# liliumSOC1_sysctrl register map
Vendor: Nordic Semiconductor; Series: liliumSOC1; File version: 1
Registers are 32-bit, read-write, reset 0x0 unless marked. A register's access mark holds for its fields unless they carry their own. Offsets are from the block's base; [hi:lo] are bit positions; lines under a group give offsets from that group; {n}, {i} and the like mark numbered series; 'fields as' and 'values as' point back to an identical list.

## POWER_S — POWER
Base 0x5F960000
0x00 TASKS_SEMAPHORE group — Peripheral tasks.
  0x00 ACQUIRE wo — Acquire the semaphore for regulator voltage scaling procedure.
    [0] ACQUIRE
      1=Trigger task
  0x04 RELEASE wo — Release the semaphore for regulator voltage scaling procedure.
    [0] RELEASE
      1=Trigger task
0x08 TASKS_REGUPDATE wo — Update the regulator configuration.
  [0] TASKS_REGUPDATE
    1=Trigger task
0x0C TASKS_TDDPDREQCLR wo — Clear the power domain request for Trace data and debug (TDD).
  [0] TASKS_TDDPDREQCLR
    1=Trigger task
0x100 EVENTS_SEMAPHORE group — Peripheral events.
  0x00 ACQUIRED — Acquired the semaphore for regulator voltage scaling procedure.
    [0] ACQUIRED
      0=NotGenerated (Event not generated); 1=Generated (Event generated)
  0x04 RELEASED — Released the semaphore for regulator voltage scaling procedure.
    [0] RELEASED
      values as EVENTS_SEMAPHORE.ACQUIRED.ACQUIRED
0x108 EVENTS_REGUPDATED — Updated the regulator configuration.
  [0] EVENTS_REGUPDATED
    values as EVENTS_SEMAPHORE.ACQUIRED.ACQUIRED
{0x10C+4i} EVENTS_ABBLOCK[{i}] (i=0..2) — Description collection: ABB lock for the ABB domain [n]
  [0] EVENTS_ABBLOCK — ABB lock for the ABB domain [n]
    values as EVENTS_SEMAPHORE.ACQUIRED.ACQUIRED
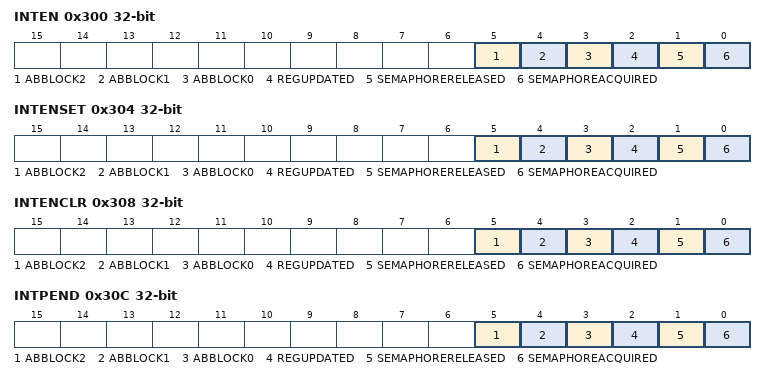
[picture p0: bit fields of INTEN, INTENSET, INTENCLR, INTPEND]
0x300 INTEN — Enable or disable interrupt
  [all] fields
    0=Disabled; 1=Enabled
  [5] ABBLOCK2 — Enable or disable interrupt for event ABBLOCK[2]
  [4] ABBLOCK1 — Enable or disable interrupt for event ABBLOCK[1]
  [3] ABBLOCK0 — Enable or disable interrupt for event ABBLOCK[0]
  [2] REGUPDATED — Enable or disable interrupt for event REGUPDATED
  [1] SEMAPHORERELEASED — Enable or disable interrupt for event SEMAPHORERELEASED
  [0] SEMAPHOREACQUIRED — Enable or disable interrupt for event SEMAPHOREACQUIRED
0x304 INTENSET — Enable interrupt
  [all] fields
    on read: 0=Disabled (Read: Disabled); 1=Enabled (Read: Enabled) | on write: 1=Set (Enable)
  [5] ABBLOCK2 — Write '1' to enable interrupt for event ABBLOCK[2]
  [4] ABBLOCK1 — Write '1' to enable interrupt for event ABBLOCK[1]
  [3] ABBLOCK0 — Write '1' to enable interrupt for event ABBLOCK[0]
  [2] REGUPDATED — Write '1' to enable interrupt for event REGUPDATED
  [1] SEMAPHORERELEASED — Write '1' to enable interrupt for event SEMAPHORERELEASED
  [0] SEMAPHOREACQUIRED — Write '1' to enable interrupt for event SEMAPHOREACQUIRED
0x308 INTENCLR — Disable interrupt
  [all] fields
    on read: 0=Disabled (Read: Disabled); 1=Enabled (Read: Enabled) | on write: 1=Clear (Disable)
  [5] ABBLOCK2 — Write '1' to disable interrupt for event ABBLOCK[2]
  [4] ABBLOCK1 — Write '1' to disable interrupt for event ABBLOCK[1]
  [3] ABBLOCK0 — Write '1' to disable interrupt for event ABBLOCK[0]
  [2] REGUPDATED — Write '1' to disable interrupt for event REGUPDATED
  [1] SEMAPHORERELEASED — Write '1' to disable interrupt for event SEMAPHORERELEASED
  [0] SEMAPHOREACQUIRED — Write '1' to disable interrupt for event SEMAPHOREACQUIRED
0x30C INTPEND ro — Pending interrupts
  [all] fields
    on read: 0=NotPending (Read: Not pending); 1=Pending (Read: Pending)
  [5] ABBLOCK2 — Read pending status of interrupt for event ABBLOCK[2]
  [4] ABBLOCK1 — Read pending status of interrupt for event ABBLOCK[1]
  [3] ABBLOCK0 — Read pending status of interrupt for event ABBLOCK[0]
  [2] REGUPDATED — Read pending status of interrupt for event REGUPDATED
  [1] SEMAPHORERELEASED — Read pending status of interrupt for event SEMAPHORERELEASED
  [0] SEMAPHOREACQUIRED — Read pending status of interrupt for event SEMAPHOREACQUIRED
0x404 DFTTAPPINENABLE — Routed to DFT tap controllers and enables target power domain.
  [1:0] ENABLE
    0=Disabled (Tap controllers disabled); 1=EnabledMain (Main tap enabled); 2=EnabledCryptoIsland (Crypto island tap enabled)
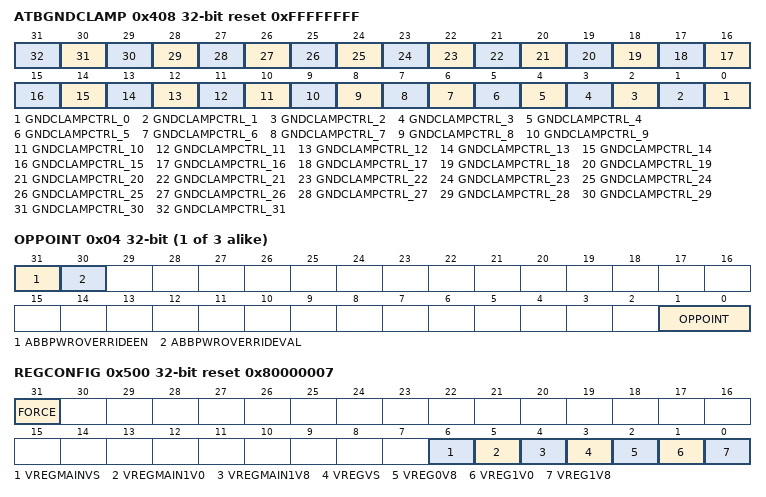
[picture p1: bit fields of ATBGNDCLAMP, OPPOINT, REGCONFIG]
0x408 ATBGNDCLAMP reset 0xFFFFFFFF — Control of ground clamps for Analog Test Bus lines.
  [all] fields
    0=Disabled (Ground clamp is disabled, net is floating); 1=Enabled (Ground clamp is enabled, net is grounded)
  [n] GNDCLAMPCTRL_{n} (n=0..31)
0x40C FORCEALLPOWERON — Forces all the power domains to remain ON.
  [0] EN — Enable the forcing all power domains to remain ON.
    0=Disabled (Forcing disabled); 1=Enabled (Forcing enabled)
{0x410+0xC*i} ABB[{i}] (i=0..2) group — Unspecified
  0x00 STATUS ro — Description cluster: ABB Status for ABB domain [n]
    [0] STATUS — ABB status
      0=Ready (The ABB is ready to accept the new operating point); 1=Busy (The ABB is busy in applying the new operating point)
  0x04 OPPOINT — Description cluster: Select ABB operating point for ABB domain [n]
    [31] ABBPWROVERRIDEEN — Enable the override of ABB analog macro powerup signal
      0=Disabled (Override disabled); 1=Enabled (Override enabled)
    [30] ABBPWROVERRIDEVAL — Override value of ABB analog macro powerup signal
      0=PowerDown (ABB analog macro powered down); 1=PowerUp (ABB analog macro powered up)
    [1:0] OPPOINT — The ABB operating point
      0=OpPoint0V4 (Operating point 0.4V); 1=OpPoint0V5 (Operating point 0.5V); 2=OpPoint0V6 (Operating point 0.6V); 3=OpPoint0V8 (Operating point 0.8V)
  0x08 FORCELOCK — Description cluster: Force lock for the ABB at ABB domain [n]
    [0] ENABLE — Enable force lock
      0=Disabled (Force lock disabled); 1=Enabled (Force lock enabled)
0x500 REGCONFIG reset 0x80000007 — Regulator configuration
  [31] FORCE — Force the regulator enable configuration
    0=Disabled (Force disabled); 1=Enabled (Force enabled)
  [6] VREGMAINVS — Enable voltage scaled rail at VREGMAIN regulator
    0=Disabled (Regulator disabled); 1=Enabled (Regulator enabled)
  [5] VREGMAIN1V0 — Enable 1.0V rail at VREGMAIN regulator
    values as VREGMAINVS
  [4] VREGMAIN1V8 — Enable 1.8V rail at VREGMAIN regulator
    values as VREGMAINVS
  [3] VREGVS — Enable voltage scaled regulator
    values as VREGMAINVS
  [2] VREG0V8 — Enable 0.8V regulator
    values as VREGMAINVS
  [1] VREG1V0 — Enable 1.0V regulator
    values as VREGMAINVS
  [0] VREG1V8 — Enable 1.8V regulator
    values as VREGMAINVS
0x504 PMICENABLE — Enable PMIC interface
  [0] ENABLE
    0=Disabled; 1=Enabled
0x508 ULPENABLE reset 0x1 — Enable ULP mode
  [0] ENABLE
    0=Disabled; 1=Enabled
0x50C ULVENABLE reset 0x1 — Enable ULV mode
  [0] ENABLE
    0=Disabled; 1=Enabled
0x510 SEMAPHORESTATUS
  [0] STATUS
    0=Released (Semaphore released); 1=Acquired (Semaphore acquired)
0x514 BILSENABLE — Enable BILS instances
  [0] ENABLE
    0=Disabled (All BILS instances are disabled); 1=Enabled (All configured BILS instances are enabled)
